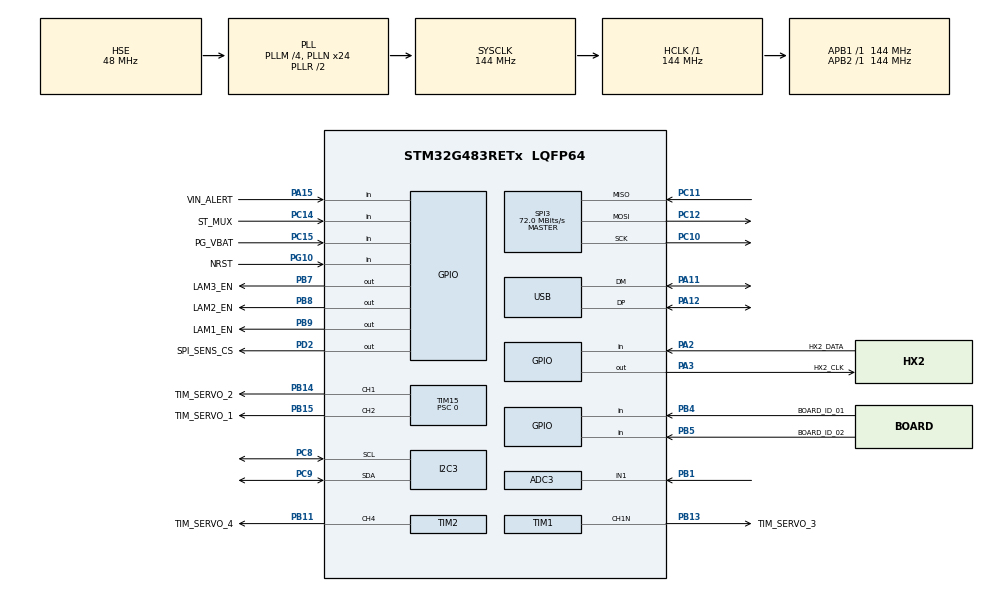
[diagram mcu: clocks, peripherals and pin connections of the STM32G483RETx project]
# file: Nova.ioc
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ADC3.Channel-0\#ChannelRegularConversion=ADC_CHANNEL_1
ADC3.NbrOfConversionFlag=1
ADC3.OffsetNumber-0\#ChannelRegularConversion=ADC_OFFSET_NONE
ADC3.Rank-0\#ChannelRegularConversion=1
ADC3.SamplingTime-0\#ChannelRegularConversion=ADC_SAMPLETIME_2CYCLES_5
ADC3.master=1
Dma.Request0=TIM2_CH4
Dma.Request1=TIM1_CH1
Dma.TIM1_CH1.1.Direction=DMA_MEMORY_TO_PERIPH
Dma.TIM1_CH1.1.EventEnable=DISABLE
Dma.TIM1_CH1.1.Instance=DMA1_Channel4
Dma.TIM1_CH1.1.MemDataAlignment=DMA_MDATAALIGN_HALFWORD
Dma.TIM1_CH1.1.MemInc=DMA_MINC_ENABLE
Dma.TIM1_CH1.1.Mode=DMA_NORMAL
Dma.TIM1_CH1.1.PeriphDataAlignment=DMA_PDATAALIGN_HALFWORD
Dma.TIM1_CH1.1.PeriphInc=DMA_PINC_DISABLE
Dma.TIM1_CH1.1.Polarity=HAL_DMAMUX_REQ_GEN_RISING
Dma.TIM1_CH1.1.Priority=DMA_PRIORITY_VERY_HIGH
Dma.TIM1_CH1.1.RequestNumber=1
Dma.TIM1_CH1.1.SignalID=NONE
Dma.TIM1_CH1.1.SyncEnable=DISABLE
Dma.TIM1_CH1.1.SyncPolarity=HAL_DMAMUX_SYNC_NO_EVENT
Dma.TIM1_CH1.1.SyncRequestNumber=1
Dma.TIM1_CH1.1.SyncSignalID=NONE
Dma.TIM2_CH4.0.Direction=DMA_MEMORY_TO_PERIPH
Dma.TIM2_CH4.0.EventEnable=DISABLE
Dma.TIM2_CH4.0.Instance=DMA1_Channel3
Dma.TIM2_CH4.0.MemDataAlignment=DMA_MDATAALIGN_HALFWORD
Dma.TIM2_CH4.0.MemInc=DMA_MINC_ENABLE
Dma.TIM2_CH4.0.Mode=DMA_NORMAL
Dma.TIM2_CH4.0.PeriphDataAlignment=DMA_PDATAALIGN_HALFWORD
Dma.TIM2_CH4.0.PeriphInc=DMA_PINC_DISABLE
Dma.TIM2_CH4.0.Polarity=HAL_DMAMUX_REQ_GEN_RISING
Dma.TIM2_CH4.0.Priority=DMA_PRIORITY_VERY_HIGH
Dma.TIM2_CH4.0.RequestNumber=1
Dma.TIM2_CH4.0.SignalID=NONE
Dma.TIM2_CH4.0.SyncEnable=DISABLE
Dma.TIM2_CH4.0.SyncPolarity=HAL_DMAMUX_SYNC_NO_EVENT
Dma.TIM2_CH4.0.SyncRequestNumber=1
Dma.TIM2_CH4.0.SyncSignalID=NONE
FREERTOS.Tasks01=defaultTask,24,128,StartDefaultTask,Default,NULL,Static,defaultTaskBuffer,defaultTaskControlBlock
FREERTOS.configENABLE_FPU=1
FREERTOS.configSUPPORT_DYNAMIC_ALLOCATION=0
FREERTOS.configTOTAL_HEAP_SIZE=30720
I2C3.Timing=0x60715075
Mcu.Family=STM32G4
Mcu.Name=STM32G483RETx
Mcu.Package=LQFP64
NVIC.DMA1_Channel3_IRQn=true\:5\:0\:false\:false\:true\:true\:false\:true\:true
NVIC.DMA1_Channel4_IRQn=true\:5\:0\:false\:false\:true\:true\:false\:true\:true
NVIC.PriorityGroup=NVIC_PRIORITYGROUP_4
NVIC.TIM6_DAC_IRQn=true\:15\:0\:false\:false\:true\:false\:false\:true\:true
NVIC.TimeBase=TIM6_DAC_IRQn
NVIC.TimeBaseIP=TIM6
NVIC.USB_LP_IRQn=true\:5\:0\:false\:false\:true\:true\:false\:true\:true
PA0.GPIO_Label=TIM_LEDS_1
PA0.Signal=S_TIM5_CH1
PA1.GPIO_Label=TIM_LEDS_2
PA1.Signal=S_TIM5_CH2
PA11.Mode=Device
PA11.Signal=USB_DM
PA12.Mode=Device
PA12.Signal=USB_DP
PA13.Mode=Trace_Asynchronous_SW
PA13.Signal=SYS_JTMS-SWDIO
PA14.Mode=Trace_Asynchronous_SW
PA14.Signal=SYS_JTCK-SWCLK
PA15.GPIO_Label=VIN_ALERT
PA15.GPIO_PuPd=GPIO_NOPULL
PA15.Signal=GPIO_Input
PA2.GPIO_Label=HX2_DATA
PA2.GPIO_PuPd=GPIO_NOPULL
PA2.Signal=GPIO_Input
PA3.GPIO_Label=HX2_CLK
PA3.GPIO_ModeDefaultOutputPP=GPIO_MODE_OUTPUT_OD
PA3.GPIO_PuPd=GPIO_NOPULL
PA3.Signal=GPIO_Output
PB1.Mode=IN1-Single-Ended
PB1.Signal=ADC3_IN1
PB11.GPIO_Label=TIM_SERVO_4
PB11.Signal=S_TIM2_CH4
PB13.GPIO_Label=TIM_SERVO_3
PB13.Mode=PWM Generation1 CH1N
PB13.Signal=TIM1_CH1N
PB14.GPIO_Label=TIM_SERVO_2
PB14.Signal=S_TIM15_CH1
PB15.GPIO_Label=TIM_SERVO_1
PB15.Signal=S_TIM15_CH2
PB3.Mode=Trace_Asynchronous_SW
PB3.Signal=SYS_JTDO-SWO
PB4.GPIO_Label=BOARD_ID_01
PB4.GPIO_PuPd=GPIO_NOPULL
PB4.Signal=GPIO_Input
PB5.GPIO_Label=BOARD_ID_02
PB5.GPIO_PuPd=GPIO_NOPULL
PB5.Signal=GPIO_Input
PB7.GPIO_Label=LAM3_EN
PB7.GPIO_ModeDefaultOutputPP=GPIO_MODE_OUTPUT_OD
PB7.GPIO_PuPd=GPIO_NOPULL
PB7.Signal=GPIO_Output
PB8-BOOT0.GPIO_Label=LAM2_EN
PB8-BOOT0.GPIO_ModeDefaultOutputPP=GPIO_MODE_OUTPUT_OD
PB8-BOOT0.GPIO_PuPd=GPIO_NOPULL
PB8-BOOT0.Signal=GPIO_Output
PB9.GPIO_Label=LAM1_EN
PB9.GPIO_ModeDefaultOutputPP=GPIO_MODE_OUTPUT_OD
PB9.GPIO_PuPd=GPIO_NOPULL
PB9.Signal=GPIO_Output
PC10.Mode=Full_Duplex_Master
PC10.Signal=SPI3_SCK
PC11.Mode=Full_Duplex_Master
PC11.Signal=SPI3_MISO
PC12.Mode=Full_Duplex_Master
PC12.Signal=SPI3_MOSI
PC14-OSC32_IN.GPIO_Label=ST_MUX
PC14-OSC32_IN.Signal=GPIO_Input
PC15-OSC32_OUT.GPIO_Label=PG_VBAT
PC15-OSC32_OUT.Signal=GPIO_Input
PC8.Mode=I2C
PC8.Signal=I2C3_SCL
PC9.Mode=I2C
PC9.Signal=I2C3_SDA
PD2.GPIO_Label=SPI_SENS_CS
PD2.GPIO_ModeDefaultOutputPP=GPIO_MODE_OUTPUT_OD
PD2.GPIO_PuPd=GPIO_NOPULL
PD2.Signal=GPIO_Output
PF0-OSC_IN.Mode=HSE-External-Oscillator
PF0-OSC_IN.Signal=RCC_OSC_IN
PF1-OSC_OUT.Mode=HSE-External-Oscillator
PF1-OSC_OUT.Signal=RCC_OSC_OUT
PG10-NRST.GPIO_Label=NRST
PG10-NRST.Signal=GPIO_Input
ProjectManager.HeapSize=0x200
ProjectManager.StackSize=0x400
ProjectManager.TargetToolchain=STM32CubeIDE
RCC.ADC12Freq_Value=144000000
RCC.ADC345Freq_Value=144000000
RCC.AHBFreq_Value=144000000
RCC.APB1Freq_Value=144000000
RCC.APB1TimFreq_Value=144000000
RCC.APB2Freq_Value=144000000
RCC.APB2TimFreq_Value=144000000
RCC.CortexFreq_Value=144000000
RCC.EXTERNAL_CLOCK_VALUE=12288000
RCC.HCLKFreq_Value=144000000
RCC.HSE_VALUE=48000000
RCC.HSI48_VALUE=48000000
RCC.HSI_VALUE=16000000
RCC.LSE_VALUE=32768
RCC.PLLM=RCC_PLLM_DIV4
RCC.PLLN=24
RCC.PLLQ=RCC_PLLQ_DIV6
RCC.PLLSourceVirtual=RCC_PLLSOURCE_HSE
RCC.SYSCLKFreq_VALUE=144000000
RCC.SYSCLKSource=RCC_SYSCLKSOURCE_PLLCLK
RCC.USBFreq_Value=48000000
RCC.VCOOutputFreq_Value=288000000
SH.S_TIM15_CH1.0=TIM15_CH1,PWM Generation1 CH1
SH.S_TIM15_CH2.0=TIM15_CH2,PWM Generation2 CH2
SH.S_TIM2_CH4.0=TIM2_CH4,PWM Generation4 CH4
SH.S_TIM5_CH1.0=TIM5_CH1
SH.S_TIM5_CH2.0=TIM5_CH2
SPI3.BaudRatePrescaler=SPI_BAUDRATEPRESCALER_2
SPI3.CalculateBaudRate=72.0 MBits/s
SPI3.Direction=SPI_DIRECTION_2LINES
SPI3.Mode=SPI_MODE_MASTER
SPI3.VirtualType=VM_MASTER
TIM1.Channel-PWM\ Generation1\ CH1N=TIM_CHANNEL_1
TIM15.Channel-PWM\ Generation1\ CH1=TIM_CHANNEL_1
TIM15.Channel-PWM\ Generation2\ CH2=TIM_CHANNEL_2
TIM15.PeriodNoDither=179
TIM15.Prescaler=0
TIM2.Channel-PWM\ Generation4\ CH4=TIM_CHANNEL_4
TIM7.PeriodNoDither=19999
TIM7.Prescaler=143
TIM7.TIM_MasterOutputTrigger=TIM_TRGO_UPDATE
USB_DEVICE.CLASS_NAME_FS=CDC
USB_DEVICE.VirtualMode=Cdc
USB_DEVICE.VirtualModeFS=Cdc_FS
VP_FREERTOS_VS_CMSIS_V2.Mode=CMSIS_V2
VP_SYS_VS_DBSignals.Mode=DisableDeadBatterySignals
VP_SYS_VS_tim6.Mode=TIM6
VP_TIM15_VS_ClockSourceINT.Mode=Internal
VP_TIM1_VS_ClockSourceITR.Mode=TriggerSource_ITR7
VP_TIM1_VS_ControllerModeReset.Mode=Reset Mode
VP_TIM2_VS_ClockSourceITR.Mode=TriggerSource_ITR7
VP_TIM2_VS_ControllerModeReset.Mode=Reset Mode
VP_TIM7_VS_ClockSourceINT.Mode=Enable_Timer
VP_USB_DEVICE_VS_USB_DEVICE_CDC_FS.Mode=CDC_FS
board=custom

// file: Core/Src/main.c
/* USER CODE BEGIN Header */
/**
  ******************************************************************************
  * @file           : main.c
  * @brief          : Main program body
  ******************************************************************************
  * @attention
  *
  * Copyright (c) 2026 STMicroelectronics.
  * All rights reserved.
  *
  * This software is licensed under terms that can be found in the LICENSE file
  * in the root directory of this software component.
  * If no LICENSE file comes with this software, it is provided AS-IS.
  *
  ******************************************************************************
  */
/* USER CODE END Header */
#include "main.h"
#include "cmsis_os.h"
#include "adc.h"
#include "dma.h"
#include "i2c.h"
#include "spi.h"
#include "tim.h"
#include "gpio.h"

/* USER CODE BEGIN Includes */
#include "Bridge.h"   /* Board_LatchMasterId */
/* USER CODE END Includes */

void SystemClock_Config(void);
void MX_FREERTOS_Init(void);

/* USER CODE BEGIN 0 */
/* Counts completed WS2812 DMA transfers (watch in Live Expressions alongside
 * ws2812ShowCalls / ws2812StartErrors). The hook releases the driver's frame
 * semaphore so the next show() can start, and returns non-zero when the
 * interrupt was the strip's.
 *
 * WHICH TIMER that is is deliberately not written here. This callback fires for
 * every PWM channel that completes a DMA transfer, so it has to be filtered -
 * but the strip's timer follows LED_STRIP_SLOT, which is C++ and unreachable
 * from main.c. Asking the driver, which knows the handle it was given, keeps the
 * one answer in one place; this file used to say TIM15 and would have gone
 * quietly deaf the moment the strip moved. */
volatile uint32_t ws2812DmaComplete = 0;

void HAL_TIM_PWM_PulseFinishedCallback(TIM_HandleTypeDef *htim)
{
	if (WS2812_FrameCompleteISR(htim))
		ws2812DmaComplete++;
}
/* USER CODE END 0 */

int main(void)
{

  /* MCU Configuration--------------------------------------------------------*/

  /* Reset of all peripherals, Initializes the Flash interface and the Systick. */
  HAL_Init();

  /* Configure the system clock */
  SystemClock_Config();

  /* Initialize all configured peripherals */
  MX_GPIO_Init();
  MX_DMA_Init();
  MX_ADC3_Init();
  MX_SPI3_Init();
  MX_TIM2_Init();
  MX_TIM1_Init();
  MX_TIM15_Init();
  MX_TIM7_Init();
  MX_I2C3_Init();
  /* USER CODE BEGIN 2 */
  /* Latch the PB4/PB5 board straps here: after MX_SPI3_Init (which owns those
   * pins as AF6) and before MX_USB_Device_Init, so the USB serial descriptor and
   * the board profile are built from one settled sample taken in thread context.
   * Without this the first sample can land inside the USB IRQ, mid-enumeration. */
  Board_LatchMasterId();
  /* USER CODE END 2 */

  /* Init scheduler */
  osKernelInitialize();  /* Call init function for freertos objects (in cmsis_os2.c) */
  MX_FREERTOS_Init();

  /* Start scheduler */
  osKernelStart();

  /* We should never get here as control is now taken by the scheduler */

  /* Infinite loop */
  while (1)
  {

  }
}

void SystemClock_Config(void)
{
  RCC_OscInitTypeDef RCC_OscInitStruct = {0};
  RCC_ClkInitTypeDef RCC_ClkInitStruct = {0};

  /** Configure the main internal regulator output voltage
  */
  HAL_PWREx_ControlVoltageScaling(PWR_REGULATOR_VOLTAGE_SCALE1);

  /** Initializes the RCC Oscillators according to the specified parameters
  * in the RCC_OscInitTypeDef structure.
  */
  RCC_OscInitStruct.OscillatorType = RCC_OSCILLATORTYPE_HSE;
  RCC_OscInitStruct.HSEState = RCC_HSE_ON;
  RCC_OscInitStruct.PLL.PLLState = RCC_PLL_ON;
  RCC_OscInitStruct.PLL.PLLSource = RCC_PLLSOURCE_HSE;
  RCC_OscInitStruct.PLL.PLLM = RCC_PLLM_DIV4;
  RCC_OscInitStruct.PLL.PLLN = 24;
  RCC_OscInitStruct.PLL.PLLP = RCC_PLLP_DIV2;
  RCC_OscInitStruct.PLL.PLLQ = RCC_PLLQ_DIV6;
  RCC_OscInitStruct.PLL.PLLR = RCC_PLLR_DIV2;
  if (HAL_RCC_OscConfig(&RCC_OscInitStruct) != HAL_OK)
  {
    Error_Handler();
  }

  /** Initializes the CPU, AHB and APB buses clocks
  */
  RCC_ClkInitStruct.ClockType = RCC_CLOCKTYPE_HCLK|RCC_CLOCKTYPE_SYSCLK
                              |RCC_CLOCKTYPE_PCLK1|RCC_CLOCKTYPE_PCLK2;
  RCC_ClkInitStruct.SYSCLKSource = RCC_SYSCLKSOURCE_PLLCLK;
  RCC_ClkInitStruct.AHBCLKDivider = RCC_SYSCLK_DIV1;
  RCC_ClkInitStruct.APB1CLKDivider = RCC_HCLK_DIV1;
  RCC_ClkInitStruct.APB2CLKDivider = RCC_HCLK_DIV1;

  if (HAL_RCC_ClockConfig(&RCC_ClkInitStruct, FLASH_LATENCY_4) != HAL_OK)
  {
    Error_Handler();
  }
}

void HAL_TIM_PeriodElapsedCallback(TIM_HandleTypeDef *htim)
{
  if (htim->Instance == TIM6)
  {
    HAL_IncTick();
  }
}

void Error_Handler(void)
{
  __disable_irq();
  while (1)
  {
  }
}

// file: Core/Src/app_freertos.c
/* USER CODE BEGIN Header */
/**
  ******************************************************************************
  * File Name          : app_freertos.c
  * Description        : Code for freertos applications
  ******************************************************************************
  * @attention
  *
  * Copyright (c) 2026 STMicroelectronics.
  * All rights reserved.
  *
  * This software is licensed under terms that can be found in the LICENSE file
  * in the root directory of this software component.
  * If no LICENSE file comes with this software, it is provided AS-IS.
  *
  ******************************************************************************
  */
/* USER CODE END Header */

#include "FreeRTOS.h"
#include "task.h"
#include "main.h"
#include "cmsis_os.h"

/* USER CODE BEGIN Includes */
#include "Bridge.h"      /* BridgeSystemInit */
#include "usb_device.h"  /* MX_USB_Device_Init */
/* USER CODE END Includes */

typedef StaticTask_t osStaticThreadDef_t;

/* Definitions for defaultTask */
osThreadId_t defaultTaskHandle;
uint32_t defaultTaskBuffer[ 128 ];
osStaticThreadDef_t defaultTaskControlBlock;
const osThreadAttr_t defaultTask_attributes = {
  .name = "defaultTask",
  .stack_mem = &defaultTaskBuffer[0],
  .stack_size = sizeof(defaultTaskBuffer),
  .cb_mem = &defaultTaskControlBlock,
  .cb_size = sizeof(defaultTaskControlBlock),
  .priority = (osPriority_t) osPriorityNormal,
};

void StartDefaultTask(void *argument);

void MX_FREERTOS_Init(void); /* (MISRA C 2004 rule 8.1) */

void MX_FREERTOS_Init(void) {

  /* USER CODE BEGIN RTOS_QUEUES */
  /* USB first, then the application threads. Both run here rather than in
   * main() because this is the window between osKernelInitialize() and
   * osKernelStart(): the kernel exists, so static queues and tasks can be
   * created, but nothing is scheduled yet.
   *
   * Order matters. MX_USB_Device_Init() asserts the D+ pull-up, so the host
   * starts enumerating while System::init() is still running - which is fine
   * because the CDC stack is interrupt-driven, but it does mean anything that
   * blocks with interrupts masked in System::init() kills enumeration. See
   * Board_LatchMasterId() in main(), which samples the board straps before any
   * of this so the USB serial descriptor never has to read them from an ISR. */
  MX_USB_Device_Init();
  BridgeSystemInit();
  /* USER CODE END RTOS_QUEUES */

  /* Create the thread(s) */
  /* creation of defaultTask */
  defaultTaskHandle = osThreadNew(StartDefaultTask, NULL, &defaultTask_attributes);

}

void StartDefaultTask(void *argument)
{
  /* USER CODE BEGIN StartDefaultTask */
  /* Infinite loop */
  for(;;)
  {
    osDelay(100);
  }
  /* USER CODE END StartDefaultTask */
}
